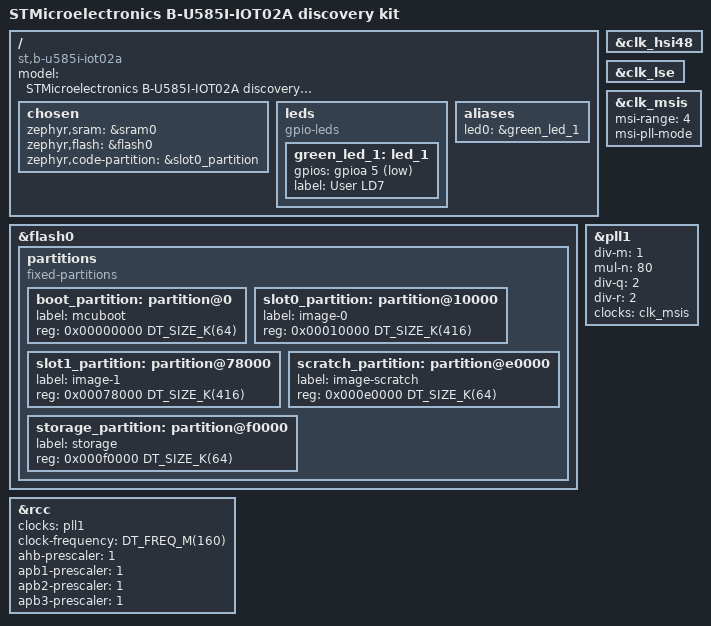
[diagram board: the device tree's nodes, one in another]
/*
 * Copyright (c) 2021 Linaro Limited
 * Copyright (c) 2024 STMicroelectronics
 *
 * SPDX-License-Identifier: Apache-2.0
 */

/dts-v1/;
#include <st/u5/stm32u585Xi.dtsi>
#include <st/u5/stm32u585aiixq-pinctrl.dtsi>
#include "arduino_r3_connector.dtsi"
#include <zephyr/dt-bindings/input/input-event-codes.h>

/ {
        model = "STMicroelectronics B-U585I-IOT02A discovery kit";
        compatible = "st,b-u585i-iot02a";

        chosen {
                zephyr,sram = &sram0;
                zephyr,flash = &flash0;
                zephyr,code-partition = &slot0_partition;
        };
        leds {
                compatible = "gpio-leds";
                green_led_1: led_1 {
                        gpios = <&gpioa 5 GPIO_ACTIVE_LOW>;
                        label = "User LD7";
                };

        };

        aliases {
                led0=&green_led_1;
        };
};

&flash0 {
        partitions {
                compatible = "fixed-partitions";
                #address-cells = <1>;
                #size-cells = <1>;

                /*
                 * Following flash partition is dedicated to the use of b_u585i_iot02a
                 * with TZEN=0 (so w/o TFM).
                 * Set the partitions with first MB to make use of the whole Bank1
                 */
                boot_partition: partition@0 {
                        label = "mcuboot";
                        reg = <0x00000000 DT_SIZE_K(64)>;
                };
                slot0_partition: partition@10000 {
                        label = "image-0";
                        reg = <0x00010000 DT_SIZE_K(416)>;
                };
                slot1_partition: partition@78000 {
                        label = "image-1";
                        reg = <0x00078000 DT_SIZE_K(416)>;
                };
                scratch_partition: partition@e0000 {
                        label = "image-scratch";
                        reg = <0x000e0000 DT_SIZE_K(64)>;
                };
                storage_partition: partition@f0000 {
                        label = "storage";
                        reg = <0x000f0000 DT_SIZE_K(64)>;
                };

        };
};






&clk_hsi48 {
        status = "okay";
};

&clk_lse {
        status = "okay";
};

&clk_msis {
        status = "okay";
        msi-range = <4>;
        msi-pll-mode;
};

&pll1 {
        div-m = <1>;
        mul-n = <80>;
        div-q = <2>;
        div-r = <2>;
        clocks = <&clk_msis>;
        status = "okay";
};

&rcc {
        clocks = <&pll1>;
        clock-frequency = <DT_FREQ_M(160)>;
        ahb-prescaler = <1>;
        apb1-prescaler = <1>;
        apb2-prescaler = <1>;
        apb3-prescaler = <1>;
};




